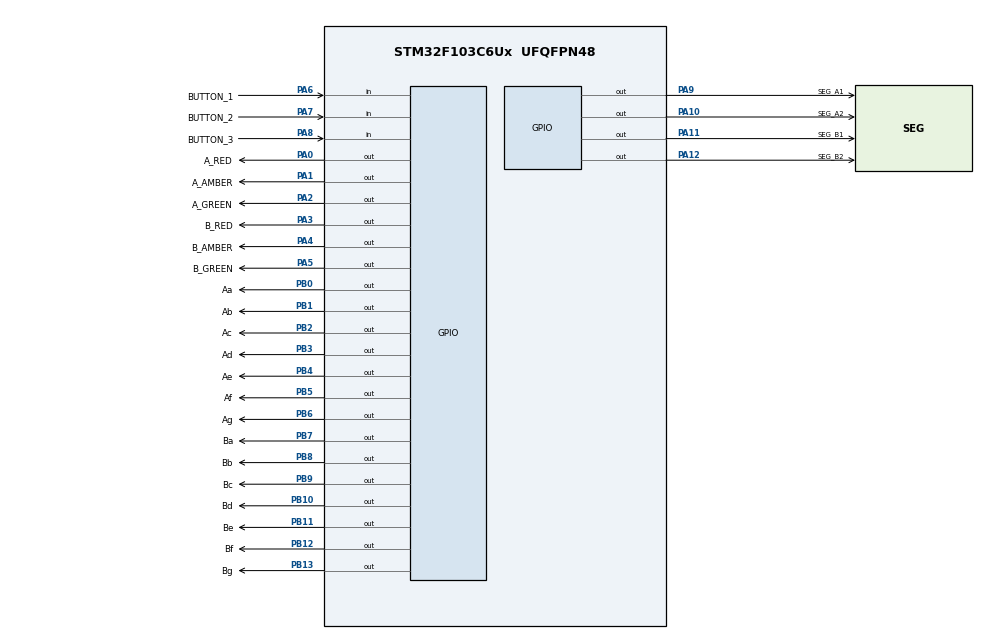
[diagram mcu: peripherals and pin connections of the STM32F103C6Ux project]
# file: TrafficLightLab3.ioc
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Mcu.Family=STM32F1
Mcu.Name=STM32F103C6Ux
Mcu.Package=UFQFPN48
NVIC.PriorityGroup=NVIC_PRIORITYGROUP_4
NVIC.TIM2_IRQn=true\:0\:0\:false\:false\:true\:true\:true
PA0-WKUP.GPIO_Label=A_RED
PA0-WKUP.Signal=GPIO_Output
PA1.GPIO_Label=A_AMBER
PA1.Signal=GPIO_Output
PA10.GPIO_Label=SEG_A2
PA10.Signal=GPIO_Output
PA11.GPIO_Label=SEG_B1
PA11.Signal=GPIO_Output
PA12.GPIO_Label=SEG_B2
PA12.Signal=GPIO_Output
PA2.GPIO_Label=A_GREEN
PA2.Signal=GPIO_Output
PA3.GPIO_Label=B_RED
PA3.Signal=GPIO_Output
PA4.GPIO_Label=B_AMBER
PA4.Signal=GPIO_Output
PA5.GPIO_Label=B_GREEN
PA5.Signal=GPIO_Output
PA6.GPIO_Label=BUTTON_1
PA6.GPIO_PuPd=GPIO_PULLUP
PA6.Signal=GPIO_Input
PA7.GPIO_Label=BUTTON_2
PA7.GPIO_PuPd=GPIO_PULLUP
PA7.Signal=GPIO_Input
PA8.GPIO_Label=BUTTON_3
PA8.GPIO_PuPd=GPIO_PULLUP
PA8.Signal=GPIO_Input
PA9.GPIO_Label=SEG_A1
PA9.Signal=GPIO_Output
PB0.GPIO_Label=Aa
PB0.Signal=GPIO_Output
PB1.GPIO_Label=Ab
PB1.Signal=GPIO_Output
PB10.GPIO_Label=Bd
PB10.Signal=GPIO_Output
PB11.GPIO_Label=Be
PB11.Signal=GPIO_Output
PB12.GPIO_Label=Bf
PB12.Signal=GPIO_Output
PB13.GPIO_Label=Bg
PB13.Signal=GPIO_Output
PB2.GPIO_Label=Ac
PB2.Signal=GPIO_Output
PB3.GPIO_Label=Ad
PB3.Signal=GPIO_Output
PB4.GPIO_Label=Ae
PB4.Signal=GPIO_Output
PB5.GPIO_Label=Af
PB5.Signal=GPIO_Output
PB6.GPIO_Label=Ag
PB6.Signal=GPIO_Output
PB7.GPIO_Label=Ba
PB7.Signal=GPIO_Output
PB8.GPIO_Label=Bb
PB8.Signal=GPIO_Output
PB9.GPIO_Label=Bc
PB9.Signal=GPIO_Output
ProjectManager.HeapSize=0x200
ProjectManager.StackSize=0x400
ProjectManager.TargetToolchain=STM32CubeIDE
RCC.APB1Freq_Value=8000000
RCC.APB2Freq_Value=8000000
TIM2.Period=9
TIM2.Prescaler=7999
VP_SYS_VS_ND.Mode=No_Debug
VP_TIM2_VS_ClockSourceINT.Mode=Internal
board=custom

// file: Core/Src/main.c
/* USER CODE BEGIN Header */
/**
  ******************************************************************************
  * @file           : main.c
  * @brief          : Main program body
  ******************************************************************************
  * @attention
  *
  * <h2><center>&copy; Copyright (c) 2026 STMicroelectronics.
  * All rights reserved.</center></h2>
  *
  * This software component is licensed by ST under BSD 3-Clause license,
  * the "License"; You may not use this file except in compliance with the
  * License. You may obtain a copy of the License at:
  *                        opensource.org/licenses/BSD-3-Clause
  *
  ******************************************************************************
  */
/* USER CODE END Header */
#include "main.h"

/* USER CODE BEGIN Includes */
#include "timer.h"
#include "led_display.h"
#include "fsm_setting.h"
/* USER CODE END Includes */

TIM_HandleTypeDef htim2;

void SystemClock_Config(void);
static void MX_GPIO_Init(void);
static void MX_TIM2_Init(void);

int main(void)
{

  /* MCU Configuration--------------------------------------------------------*/

  /* Reset of all peripherals, Initializes the Flash interface and the Systick. */
  HAL_Init();

  /* Configure the system clock */
  SystemClock_Config();

  /* Initialize all configured peripherals */
  MX_GPIO_Init();
  MX_TIM2_Init();
  /* USER CODE BEGIN 2 */
  if (HAL_TIM_Base_Start_IT(&htim2) != HAL_OK)
  {
      Error_Handler();
  }
    clearAllLEDs();
    setTimer3(250); // Toggle every 250 ms: 2 Hz traffic-light blinking
    setTimer4(10);  // Switch digit pairs every 10 ms: 50 Hz per digit
  /* USER CODE END 2 */

  /* Infinite loop */
  /* USER CODE BEGIN WHILE */
  while (1)
  {
	  if (timer4_flag == 1) { // Quét LED 7 đoạn mượt mà độc lập với vòng lặp chính
	            update7SEG();
	            setTimer4(10);
	        }

	    fsm_mode_processing(); // Xử lý đ�?c nút nhấn và các Mode
    /* USER CODE END WHILE */
	    __DSB();
	    __WFI();
  }
}

void SystemClock_Config(void)
{
  RCC_OscInitTypeDef RCC_OscInitStruct = {0};
  RCC_ClkInitTypeDef RCC_ClkInitStruct = {0};

  /** Initializes the RCC Oscillators according to the specified parameters
  * in the RCC_OscInitTypeDef structure.
  */
  RCC_OscInitStruct.OscillatorType = RCC_OSCILLATORTYPE_HSI;
  RCC_OscInitStruct.HSIState = RCC_HSI_ON;
  RCC_OscInitStruct.HSICalibrationValue = RCC_HSICALIBRATION_DEFAULT;
  RCC_OscInitStruct.PLL.PLLState = RCC_PLL_NONE;
  if (HAL_RCC_OscConfig(&RCC_OscInitStruct) != HAL_OK)
  {
    Error_Handler();
  }
  /** Initializes the CPU, AHB and APB buses clocks
  */
  RCC_ClkInitStruct.ClockType = RCC_CLOCKTYPE_HCLK|RCC_CLOCKTYPE_SYSCLK
                              |RCC_CLOCKTYPE_PCLK1|RCC_CLOCKTYPE_PCLK2;
  RCC_ClkInitStruct.SYSCLKSource = RCC_SYSCLKSOURCE_HSI;
  RCC_ClkInitStruct.AHBCLKDivider = RCC_SYSCLK_DIV1;
  RCC_ClkInitStruct.APB1CLKDivider = RCC_HCLK_DIV1;
  RCC_ClkInitStruct.APB2CLKDivider = RCC_HCLK_DIV1;

  if (HAL_RCC_ClockConfig(&RCC_ClkInitStruct, FLASH_LATENCY_0) != HAL_OK)
  {
    Error_Handler();
  }
}

static void MX_TIM2_Init(void)
{

  TIM_ClockConfigTypeDef sClockSourceConfig = {0};
  TIM_MasterConfigTypeDef sMasterConfig = {0};

  htim2.Instance = TIM2;
  htim2.Init.Prescaler = 7999;
  htim2.Init.CounterMode = TIM_COUNTERMODE_UP;
  htim2.Init.Period = 9;
  htim2.Init.ClockDivision = TIM_CLOCKDIVISION_DIV1;
  htim2.Init.AutoReloadPreload = TIM_AUTORELOAD_PRELOAD_DISABLE;
  if (HAL_TIM_Base_Init(&htim2) != HAL_OK)
  {
    Error_Handler();
  }
  sClockSourceConfig.ClockSource = TIM_CLOCKSOURCE_INTERNAL;
  if (HAL_TIM_ConfigClockSource(&htim2, &sClockSourceConfig) != HAL_OK)
  {
    Error_Handler();
  }
  sMasterConfig.MasterOutputTrigger = TIM_TRGO_RESET;
  sMasterConfig.MasterSlaveMode = TIM_MASTERSLAVEMODE_DISABLE;
  if (HAL_TIMEx_MasterConfigSynchronization(&htim2, &sMasterConfig) != HAL_OK)
  {
    Error_Handler();
  }

}

static void MX_GPIO_Init(void)
{
  GPIO_InitTypeDef GPIO_InitStruct = {0};

  /* GPIO Ports Clock Enable */
  __HAL_RCC_GPIOA_CLK_ENABLE();
  __HAL_RCC_GPIOB_CLK_ENABLE();

  /*Configure GPIO pin Output Level */
  HAL_GPIO_WritePin(GPIOA, A_RED_Pin|A_AMBER_Pin|A_GREEN_Pin|B_RED_Pin
                          |B_AMBER_Pin|B_GREEN_Pin|SEG_A1_Pin|SEG_A2_Pin
                          |SEG_B1_Pin|SEG_B2_Pin, GPIO_PIN_SET);

  /*Configure GPIO pin Output Level */
  HAL_GPIO_WritePin(GPIOB, Aa_Pin|Ab_Pin|Ac_Pin|Bd_Pin
                          |Be_Pin|Bf_Pin|Bg_Pin|Ad_Pin
                          |Ae_Pin|Af_Pin|Ag_Pin|Ba_Pin
                          |Bb_Pin|Bc_Pin, GPIO_PIN_SET);

  /*Configure GPIO pins : A_RED_Pin A_AMBER_Pin A_GREEN_Pin B_RED_Pin
                           B_AMBER_Pin B_GREEN_Pin SEG_A1_Pin SEG_A2_Pin
                           SEG_B1_Pin SEG_B2_Pin */
  GPIO_InitStruct.Pin = A_RED_Pin|A_AMBER_Pin|A_GREEN_Pin|B_RED_Pin
                          |B_AMBER_Pin|B_GREEN_Pin|SEG_A1_Pin|SEG_A2_Pin
                          |SEG_B1_Pin|SEG_B2_Pin;
  GPIO_InitStruct.Mode = GPIO_MODE_OUTPUT_PP;
  GPIO_InitStruct.Pull = GPIO_NOPULL;
  GPIO_InitStruct.Speed = GPIO_SPEED_FREQ_LOW;
  HAL_GPIO_Init(GPIOA, &GPIO_InitStruct);

  /*Configure GPIO pins : BUTTON_1_Pin BUTTON_2_Pin BUTTON_3_Pin */
  GPIO_InitStruct.Pin = BUTTON_1_Pin|BUTTON_2_Pin|BUTTON_3_Pin;
  GPIO_InitStruct.Mode = GPIO_MODE_INPUT;
  GPIO_InitStruct.Pull = GPIO_PULLUP;
  HAL_GPIO_Init(GPIOA, &GPIO_InitStruct);

  /*Configure GPIO pins : Aa_Pin Ab_Pin Ac_Pin Bd_Pin
                           Be_Pin Bf_Pin Bg_Pin Ad_Pin
                           Ae_Pin Af_Pin Ag_Pin Ba_Pin
                           Bb_Pin Bc_Pin */
  GPIO_InitStruct.Pin = Aa_Pin|Ab_Pin|Ac_Pin|Bd_Pin
                          |Be_Pin|Bf_Pin|Bg_Pin|Ad_Pin
                          |Ae_Pin|Af_Pin|Ag_Pin|Ba_Pin
                          |Bb_Pin|Bc_Pin;
  GPIO_InitStruct.Mode = GPIO_MODE_OUTPUT_PP;
  GPIO_InitStruct.Pull = GPIO_NOPULL;
  GPIO_InitStruct.Speed = GPIO_SPEED_FREQ_LOW;
  HAL_GPIO_Init(GPIOB, &GPIO_InitStruct);

}

void Error_Handler(void)
{
  __disable_irq();
  while (1)
  {
  }
}

/************************ (C) COPYRIGHT STMicroelectronics *****END OF FILE****/
